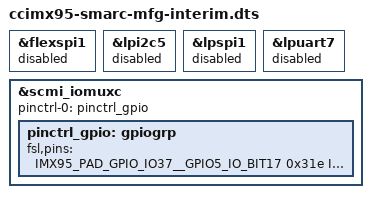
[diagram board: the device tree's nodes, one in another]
// SPDX-License-Identifier: (GPL-2.0+ OR MIT)
/*
 * Copyright 2025-2026, Digi International Inc.
 */

/dts-v1/;

/* Digi ConnectCore 95 DVK */
#include "ccimx95-dvk.dts"

&flexspi1 {
	status = "disabled";
};

&lpi2c5 {
	status = "disabled";
};

&lpspi1 {
	status = "disabled";
};

&lpuart7 {
	status = "disabled";
};

&scmi_iomuxc {
	pinctrl-names = "default";
	pinctrl-0 = <&pinctrl_gpio>;

	/* GPIOs for User Leds, Buttons, ... */
	pinctrl_gpio: gpiogrp {
		fsl,pins = <
			/* XBEE_UART_RX_3V3 - J20.2 */
			IMX95_PAD_GPIO_IO37__GPIO5_IO_BIT17	0x31e
			/* XBEE_UART_TX_3V3 - J20.3 */
			IMX95_PAD_GPIO_IO36__GPIO5_IO_BIT16	0x31e
			/* XBEE_RESET#_3V3 - J20.5 */
			IMX95_PAD_SD2_RESET_B__GPIO3_IO_BIT7	0x31e
			/* XBEE_UART_RTS_3V3 - J21.5 */
			IMX95_PAD_GPIO_IO11__GPIO2_IO_BIT11	0x31e
			/* XBEE_UART_CTS_3V3 - J21.9 */
			IMX95_PAD_GPIO_IO10__GPIO2_IO_BIT10	0x31e

			/* GPIO4_IO29 - J22.1 */
			IMX95_PAD_CCM_CLKO4__GPIO4_IO_BIT29	0x31e
			/* GPIO3_IO27 - J22.1 */
			IMX95_PAD_CCM_CLKO2__GPIO3_IO_BIT27	0x31e

			/* I2C5_SCL - J23.2 */
			IMX95_PAD_GPIO_IO23__GPIO2_IO_BIT23	0x31e
			/* I2C5_SDA - J23.3 */
			IMX95_PAD_GPIO_IO22__GPIO2_IO_BIT22	0x31e

			/* SPI1_SS0 - J24.1 */
			IMX95_PAD_SAI1_TXFS__AONMIX_TOP_GPIO1_IO_BIT11	0x31e
			/* SPI1_SS1 - J24.2 */
			IMX95_PAD_PDM_BIT_STREAM0__AONMIX_TOP_GPIO1_IO_BIT9	0x31e
			/* SPI1_SCK - J24.3 */
			IMX95_PAD_SAI1_TXD0__AONMIX_TOP_GPIO1_IO_BIT13	0x31e
			/* SPI1_MISO - J24.4 */
			IMX95_PAD_SAI1_TXC__AONMIX_TOP_GPIO1_IO_BIT12	0x31e
			/* SPI1_MOSI - J24.5 */
			IMX95_PAD_SAI1_RXD0__AONMIX_TOP_GPIO1_IO_BIT14	0x31e

			/* SAI5_TXFS - J25.2 */
			IMX95_PAD_XSPI1_DATA5__GPIO5_IO_BIT5	0x31e
			/* SAI5_TXD - J25.3 */
			IMX95_PAD_XSPI1_DATA4__GPIO5_IO_BIT4	0x31e
			/* SAI5_RXD - J25.4 */
			IMX95_PAD_XSPI1_DATA7__GPIO5_IO_BIT7	0x31e
			/* SAI5_TXC - J25.5 */
			IMX95_PAD_XSPI1_DATA6__GPIO5_IO_BIT6	0x31e

			/* XSPI1_SCLK - J26.1 */
			IMX95_PAD_XSPI1_SCLK__GPIO5_IO_BIT9	0x31e
			/* XSPI1_SS0 - J26.2 */
			IMX95_PAD_XSPI1_SS0_B__GPIO5_IO_BIT10	0x31e
			/* XSPI1_DATA0 - J26.3 */
			IMX95_PAD_XSPI1_DATA0__GPIO5_IO_BIT0	0x31e
			/* XSPI1_SS1 - J26.4 */
			IMX95_PAD_XSPI1_SS1_B__GPIO5_IO_BIT11	0x31e
			/* XSPI1_DATA1 - J26.5 */
			IMX95_PAD_XSPI1_DATA1__GPIO5_IO_BIT1	0x31e
			/* XSPI1_ALERT0# - J26.6 */
			IMX95_PAD_XSPI1_DQS__GPIO5_IO_BIT8	0x31e
			/* XSPI1_DATA2 - J26.7 */
			IMX95_PAD_XSPI1_DATA2__GPIO5_IO_BIT2	0x31e
			/* XSPI1_DATA3 - J26.9 */
			IMX95_PAD_XSPI1_DATA3__GPIO5_IO_BIT3	0x31e
		>;
	};
};
